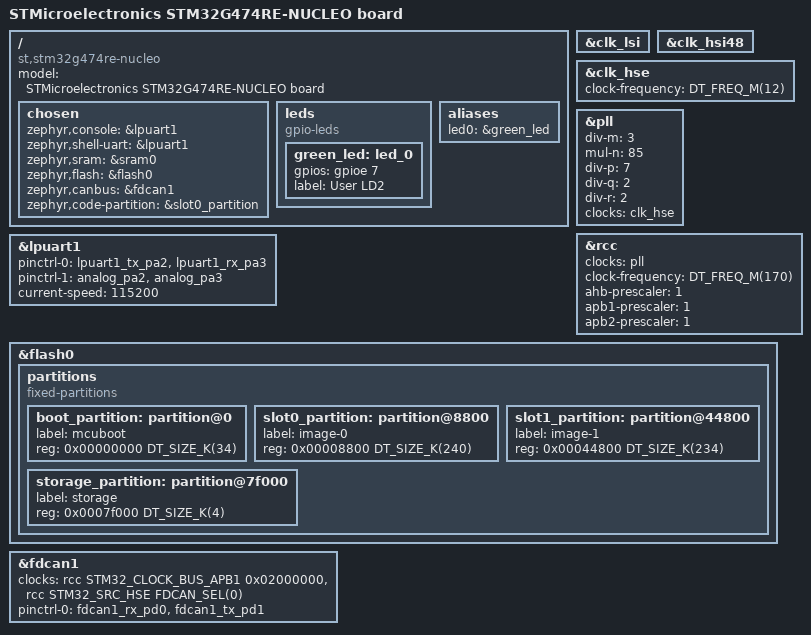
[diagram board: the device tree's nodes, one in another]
/*
 * Copyright (c) 2019 STMicroelectronics.
 *
 * SPDX-License-Identifier: Apache-2.0
 */

/dts-v1/;
#include <st/g4/stm32g473Xe.dtsi>
#include <st/g4/stm32g473v(b-c-e)tx-pinctrl.dtsi>

/ {
	model = "STMicroelectronics STM32G474RE-NUCLEO board";
	compatible = "st,stm32g474re-nucleo";

	chosen {
		zephyr,console = &lpuart1;
		zephyr,shell-uart = &lpuart1;
		zephyr,sram = &sram0;
		zephyr,flash = &flash0;
		zephyr,canbus = &fdcan1;
		zephyr,code-partition = &slot0_partition;
	};

	leds: leds {
		compatible = "gpio-leds";
		green_led: led_0 {
			gpios = <&gpioe 7 GPIO_ACTIVE_HIGH>;
			label = "User LD2";
		};
	};

	aliases {
		led0 = &green_led;
	};
};

&clk_lsi {
	status = "okay";
};

&clk_hsi48 {
	status = "okay";
};

&clk_hse {
	clock-frequency = <DT_FREQ_M(12)>;
	status = "okay";
};

&pll {
	div-m = <3>;
	mul-n = <85>;
	div-p = <7>;
	div-q = <2>;
	div-r = <2>;
	clocks = <&clk_hse>;
	status = "okay";
};

&rcc {
	clocks = <&pll>;
	clock-frequency = <DT_FREQ_M(170)>;
	ahb-prescaler = <1>;
	apb1-prescaler = <1>;
	apb2-prescaler = <1>;
};

&lpuart1 {
	pinctrl-0 = <&lpuart1_tx_pa2 &lpuart1_rx_pa3>;
	pinctrl-1 = <&analog_pa2 &analog_pa3>;
	pinctrl-names = "default", "sleep";
	current-speed = <115200>;
	status = "okay";
};


&flash0 {
	partitions {
		compatible = "fixed-partitions";
		#address-cells = <1>;
		#size-cells = <1>;

		boot_partition: partition@0 {
			label = "mcuboot";
			reg = <0x00000000 DT_SIZE_K(34)>;
		};
		slot0_partition: partition@8800 {
			label = "image-0";
			reg = <0x00008800 DT_SIZE_K(240)>;
		};
		slot1_partition: partition@44800 {
			label = "image-1";
			reg = <0x00044800 DT_SIZE_K(234)>;
		};
		/* Set 4Kb of storage at the end of the 512Kb of flash */
		storage_partition: partition@7f000 {
			label = "storage";
			reg = <0x0007f000 DT_SIZE_K(4)>;
		};
	};
};


&fdcan1 {
	clocks = <&rcc STM32_CLOCK_BUS_APB1 0x02000000>,
		 <&rcc STM32_SRC_HSE FDCAN_SEL(0)>;
	pinctrl-0 = <&fdcan1_rx_pd0 &fdcan1_tx_pd1>;
	pinctrl-names = "default";
	status = "okay";
};

